# AT32F421xx_v2 register map
Vendor: Keil; Series: AT32F421; File version: 1.0
ARM 32-bit Cortex-M4 Microcontroller based device, CPU clock up to 200MHz, etc.
CPU: CM4 r0p1, little endian, no MPU, FPU, 4 interrupt priority bits
Registers are 32-bit, read-write, reset 0x0 unless marked. A register's access mark holds for its fields unless they carry their own. Offsets are from the block's base; lines under a group give offsets from that group; [hi:lo] are bit positions; {n}, {i} and the like mark numbered series; 'fields as' and 'values as' point back to an identical list; <NAME> marks a mode.

## Memory map
0x40000400 TMR3 size 0x400 — General purpose timer
0x40001000 TMR6 size 0x400 — Basic timer
0x40002000 TMR14 size 0x400 — General purpose timer
0x40002800 ERTC size 0x400 — Real-time clock
0x40002C00 WWDT size 0x400 — Window watchdog
0x40003000 WDT size 0x400 — Watchdog
0x40003800 SPI2 size 0x400
0x40004400 USART2 size 0x400
0x40005400 I2C1 size 0x400 — Inter integrated circuit
0x40005800 I2C2 size 0x400
0x40007000 PWC size 0x400 — Power control
0x40010000 SCFG size 0x1C — System configuration controller
0x4001001C CMP size 0x3E4 — Comparator
0x40010400 EXINT size 0x400
0x40012400 ADC size 0x400 — Analog to digital converter
0x40012C00 TMR1 size 0x400 — Advanced timer
0x40013000 SPI1 size 0x400 — Serial peripheral interface
0x40013800 USART1 size 0x400 — Universal synchronous asynchronous receiver transmitter
0x40014000 TMR15 size 0x400 — Advanced timer
0x40014400 TMR16 size 0x400 — General purpose timer
0x40014800 TMR17 size 0x400
0x40020000 DMA1 size 0x400 — DMA controller
0x40021000 CRM size 0x400 — Clock and reset management
0x40022000 FLASH size 0x400 — Flash memory controler
0x40023000 CRC size 0x400 — CRC calculation unit
0x48000000 GPIOA size 0x400 — General purpose I/Os
0x48000400 GPIOB size 0x400
0x48000800 GPIOC size 0x400
0x48001400 GPIOF size 0x400
0xE000E000 NVIC size 0x1001 — Nested Vectored Interrupt Controller
0xE0042000 DEBUG size 0x400 — Debug support

## Interrupts
0 WWDT — Window Watchdog interrupt
1 PVM (EXINT) — PVM interrupt connect to EXTI line16
2 ERTC (EXINT) — ERTC interrupt connect to EXTI line17_19
3 FLASH — Flash global interrupt
4 CRM — CRM global interrupt
5 EXTINT1_0 (EXINT) — EXINT Line1_0 interrupt
6 EXTINT3_2 (EXINT) — EXINT Line3_2 interrupt
7 EXTINT15_4 (EXINT) — EXINT Line15_4 interrupt
9 DMA1_Channel1 (DMA1) — DMA1 Channel1 global interrupt
10 DMA1_Channel3_2 (DMA1) — DMA1 Channel2 global interrupt
11 DMA1_Channel5_4 (DMA1) — DMA1 Channel3 global interrupt
12 ADC_CMP (CMP) — ADC and CMP interrupt
13 TMR1_BRK_OVF_TRG_HALL (TMR1) — TMR1 overflow brake trigger hall interrupt
14 TMR1_CH (TMR1) — TMR1 channel interrupt
16 TMR3 — TMR3 global interrupt
17 TMR6 — TMR6 global interrupt
18 ADC1_2 (ADC) — ADC1 and ADC2 global interrupt
19 TMR14 — TMR14 global interrupt
20 TMR15 — TMR15 global interrupt
21 TMR16 — TMR16 global interrupt
22 TMR17 — TMR17 global interrupt
27 USART1 — USART1 global interrupt
28 USART2 — USART2 global interrupt
31 I2C1_EVT (I2C1) — I2C1 event interrupt
32 I2C1_ERR (I2C1) — I2C1 error interrupt
33 I2C2_EVT (I2C2) — I2C2 event interrupt
34 I2C2_ERR (I2C2) — I2C2 error interrupt
35 SPI1 — SPI1 global interrupt
36 SPI2 — SPI2 global interrupt

## PWC — Power control
Base 0x40007000
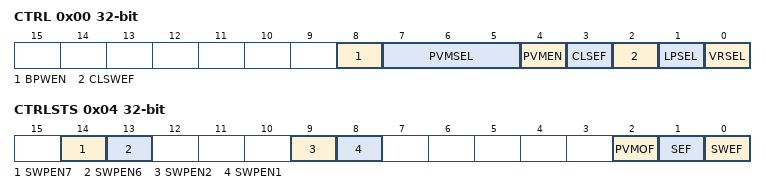
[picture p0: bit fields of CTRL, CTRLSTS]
0x00 CTRL — Power control register (PWC_CTRL)
  [8] BPWEN — Battery powered domain write enable
  [7:5] PVMSEL — Power voltage monitoring boundary select
  [4] PVMEN — Power voltage monitoring enable
  [3] CLSEF — Clear SEF flag
  [2] CLSWEF — Clear SWEF flag
  [1] LPSEL — Low power mode select when Cortex-M4F sleepdeep
  [0] VRSEL — Voltage regulator state select when deepsleep mode
0x04 CTRLSTS — Power control and status register (PWC_CTRLSTS)
  [14] SWPEN7 — Standby wake-up pin2 enable
  [13] SWPEN6 — Standby wake-up pin2 enable
  [9] SWPEN2 — Standby wake-up pin2 enable
  [8] SWPEN1 — Standby wake-up pin1 enable
  [2] PVMOF ro — Power voltage monitoring output flag
  [1] SEF ro — Standby mode entry flag
  [0] SWEF ro — Standby wake-up event flag
0x20 CTRL2 — Power control and status register2 (PWC_CTRL2)
  [5] VREXLPEN — Voltage regulator extra low power mode enable

## Licence text in the file
ARM Limited (ARM) is supplying this software for use with Cortex-M processor based microcontroller, but can be equally used for other suitable processor architectures. This file can be freely distributed. Modifications to this file shall be clearly marked. . THIS SOFTWARE IS PROVIDED "AS IS". NO WARRANTIES, WHETHER EXPRESS, IMPLIED. OR STATUTORY, INCLUDING, BUT NOT LIMITED TO, IMPLIED WARRANTIES OF. MERCHANTABILITY AND FITNESS FOR A PARTICULAR PURPOSE APPLY TO THIS SOFTWARE. ARM SHALL NOT, IN ANY CIRCUMSTANCES, BE LIABLE FOR SPECIAL, INCIDENTAL, OR. CONSEQUENTIAL DAMAGES, FOR ANY REASON WHATSOEVER.

## Notices in the file
Copyright (C) 2012-2014 ARM Limited. All rights reserved.
Purpose: System Viewer Description (SVD) Example (Schema Version 1.1)
This is a description of a none-existent and incomplete device
for demonstration purposes only.
Redistribution and use in source and binary forms, with or without
modification, are permitted provided that the following conditions are met:
- Redistributions of source code must retain the above copyright
notice, this list of conditions and the following disclaimer.
- Redistributions in binary form must reproduce the above copyright
notice, this list of conditions and the following disclaimer in the
documentation and/or other materials provided with the distribution.
- Neither the name of ARM nor the names of its contributors may be used
to endorse or promote products derived from this software without
specific prior written permission.
THIS SOFTWARE IS PROVIDED BY THE COPYRIGHT HOLDERS AND CONTRIBUTORS "AS IS"
AND ANY EXPRESS OR IMPLIED WARRANTIES, INCLUDING, BUT NOT LIMITED TO, THE
ARE DISCLAIMED. IN NO EVENT SHALL COPYRIGHT HOLDERS AND CONTRIBUTORS BE
LIABLE FOR ANY DIRECT, INDIRECT, INCIDENTAL, SPECIAL, EXEMPLARY, OR
CONSEQUENTIAL DAMAGES (INCLUDING, BUT NOT LIMITED TO, PROCUREMENT OF
SUBSTITUTE GOODS OR SERVICES; LOSS OF USE, DATA, OR PROFITS; OR BUSINESS
INTERRUPTION) HOWEVER CAUSED AND ON ANY THEORY OF LIABILITY, WHETHER IN
CONTRACT, STRICT LIABILITY, OR TORT (INCLUDING NEGLIGENCE OR OTHERWISE)
ARISING IN ANY WAY OUT OF THE USE OF THIS SOFTWARE, EVEN IF ADVISED OF THE
POSSIBILITY OF SUCH DAMAGE.
